# PCIE_CFG register map
Vendor: Texas Instruments
Peripheral module from a debugger description file (folder 66AK2G0x_66AK2G1x).
Registers are 32-bit, read-only, reset 0x104C unless marked. A register's access mark holds for its fields unless they carry their own. Offsets are as the file gives them; lines under a group give offsets from that group; [hi:lo] are bit positions; {n}, {i} and the like mark numbered series; 'fields as' and 'values as' point back to an identical list; <NAME> marks a mode.

## PCIE_CFG
0x1000 PCIE_VENDOR_DEVICE_ID
  [31:0] REV — TI internal data. Identifies revision of peripheral.
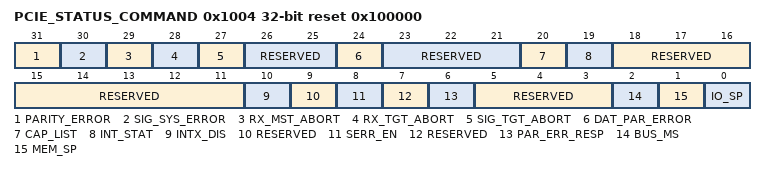
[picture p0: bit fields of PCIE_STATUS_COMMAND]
0x1004 PCIE_STATUS_COMMAND access not given reset 0x100000
  [31] PARITY_ERROR — Set if function receives poisoned TLP. (access RW1C)
  [30] SIG_SYS_ERROR — Set if function sends an ERR_FATAL or ERR_NONFATAL message and SERR enable bit is set to one. (access RW1C)
  [29] RX_MST_ABORT — Set when a requester receives a completion with unsupported request completion status. (access RW1C)
  [28] RX_TGT_ABORT — Set when a requester receives a completion with completer abort status. (access RW1C)
  [27] SIG_TGT_ABORT — Set when a function acting as a completer terminates a request by issuing completer abort completion status to the requester. (access RW1C)
  [26:25] RESERVED ro — Reads return 0 and writes have no effect.
  [24] DAT_PAR_ERROR — This bit is set by a requester if the Parity Error Enable bit is set in its Command register and either the condition that the requester receives a poisoned completion or the condition that the requester poisons a write request is true. (access RW1C)
  [23:21] RESERVED ro — Reads return 0 and writes have no effect.
  [20] CAP_LIST ro — For PCIe, this field must be set to 1.
  [19] INT_STAT ro — Indicates that the function has received an interrupt.
  [18:11] RESERVED ro — Reads return 0 and writes have no effect.
  [10] INTX_DIS rw — Setting this bit disables generation of INTx messages.
  [9] RESERVED ro — Reads return 0 and writes have no effect.
  [8] SERR_EN rw — When set, it enables generation of the appropriate PCI Express error messages to the Root Complex.
  [7] RESERVED ro — Reads return 0 and writes have no effect.
  [6] PAR_ERR_RESP rw — This bit controls whether or not the device responds to detected parity errors (poisoned TLP). This error is typically reported as an unsupported request and may also result in a non-fatal error message if SERR_EN=1. If this bit is set, the PCIESS will respond normally to parity errors. If this bit is cleared, the PCIESS will ignore detected parity errors.
  [5:3] RESERVED ro — Reads return 0 and writes have no effect.
  [2] BUS_MS rw — Enables mastership of the bus.
  [1] MEM_SP rw — This bit is set to enable the device to respond to memory accesses.
  [0] IO_SP rw — This bit is set to enable the device to respond to I/O accesses. This functionality is not supported in PCIESS and therefore this bit is set to 0.
0x1008 PCIE_CLASSCODE_REVID reset 0x1
  [31:0] REV — TI internal data. Identifies revision of peripheral.
